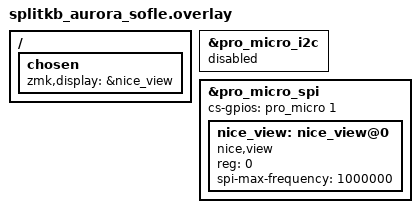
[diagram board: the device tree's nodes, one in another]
/ {
    chosen {
        zmk,display = &nice_view;
    };
};

&pro_micro_i2c {
    status = "disabled";
};

&pro_micro_spi {
    status = "okay";
    cs-gpios = <&pro_micro 1 GPIO_ACTIVE_HIGH>;

    nice_view: nice_view@0 {
        compatible = "nice,view";
        reg = <0>;
        spi-max-frequency = <1000000>;
    };
};
